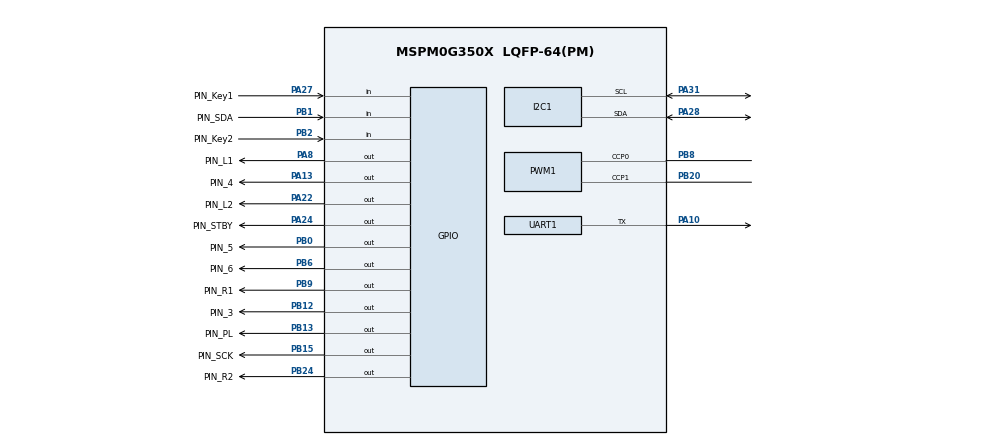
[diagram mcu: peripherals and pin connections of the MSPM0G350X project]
/**
 *
 * @cliArgs --device "MSPM0G350X" --part "Default" --package "LQFP-64(PM)" --product "mspm0_sdk@2.11.00.07"
 * @versions {"tool":"1.28.0+4696"}
 */

/**
 * Import the modules used in this configuration.
 */
const GPIO    = scripting.addModule("/ti/driverlib/GPIO", {}, false);
const GPIO1   = GPIO.addInstance();
const GPIO2   = GPIO.addInstance();
const GPIO3   = GPIO.addInstance();
const GPIO4   = GPIO.addInstance();
const GPIO5   = GPIO.addInstance();
const I2C     = scripting.addModule("/ti/driverlib/I2C", {}, false);
const I2C1    = I2C.addInstance();
const PWM     = scripting.addModule("/ti/driverlib/PWM", {}, false);
const PWM1    = PWM.addInstance();
const SYSCTL  = scripting.addModule("/ti/driverlib/SYSCTL");
const SYSTICK = scripting.addModule("/ti/driverlib/SYSTICK");
const UART    = scripting.addModule("/ti/driverlib/UART", {}, false);
const UART1   = UART.addInstance();

/**
 * Write custom configuration values to the imported modules.
 */
GPIO1.$name                          = "GPIO_Motor";
GPIO1.associatedPins.create(5);
GPIO1.associatedPins[0].$name        = "PIN_L1";
GPIO1.associatedPins[0].assignedPort = "PORTA";
GPIO1.associatedPins[0].assignedPin  = "8";
GPIO1.associatedPins[0].pin.$assign  = "PA8";
GPIO1.associatedPins[1].$name        = "PIN_L2";
GPIO1.associatedPins[1].assignedPort = "PORTA";
GPIO1.associatedPins[1].assignedPin  = "22";
GPIO1.associatedPins[1].pin.$assign  = "PA22";
GPIO1.associatedPins[2].$name        = "PIN_R1";
GPIO1.associatedPins[2].assignedPort = "PORTB";
GPIO1.associatedPins[2].assignedPin  = "9";
GPIO1.associatedPins[2].pin.$assign  = "PB9";
GPIO1.associatedPins[3].$name        = "PIN_R2";
GPIO1.associatedPins[3].assignedPort = "PORTB";
GPIO1.associatedPins[3].assignedPin  = "24";
GPIO1.associatedPins[3].pin.$assign  = "PB24";
GPIO1.associatedPins[4].$name        = "PIN_STBY";
GPIO1.associatedPins[4].assignedPort = "PORTA";
GPIO1.associatedPins[4].assignedPin  = "24";
GPIO1.associatedPins[4].pin.$assign  = "PA24";

const Board = scripting.addModule("/ti/driverlib/Board", {}, false);

GPIO2.$name                          = "GPIO_LED";
GPIO2.associatedPins[0].assignedPort = "PORTA";
GPIO2.associatedPins[0].$name        = "PIN_LED";
GPIO2.associatedPins[0].assignedPin  = "0";

GPIO3.$name                              = "GPIO_BUTTON";
GPIO3.associatedPins.create(3);
GPIO3.associatedPins[0].$name            = "PIN_BUTTON";
GPIO3.associatedPins[0].direction        = "INPUT";
GPIO3.associatedPins[0].assignedPort     = "PORTA";
GPIO3.associatedPins[0].assignedPin      = "18";
GPIO3.associatedPins[0].internalResistor = "PULL_DOWN";
GPIO3.associatedPins[1].$name            = "PIN_Key1";
GPIO3.associatedPins[1].direction        = "INPUT";
GPIO3.associatedPins[1].internalResistor = "PULL_UP";
GPIO3.associatedPins[1].pin.$assign      = "PA27";
GPIO3.associatedPins[2].$name            = "PIN_Key2";
GPIO3.associatedPins[2].direction        = "INPUT";
GPIO3.associatedPins[2].internalResistor = "PULL_UP";
GPIO3.associatedPins[2].pin.$assign      = "PB2";

GPIO4.$name                          = "GPIO_Sensor";
GPIO4.associatedPins.create(3);
GPIO4.associatedPins[0].assignedPort = "PORTB";
GPIO4.associatedPins[0].$name        = "PIN_PL";
GPIO4.associatedPins[0].pin.$assign  = "PB13";
GPIO4.associatedPins[1].$name        = "PIN_SCK";
GPIO4.associatedPins[1].assignedPort = "PORTB";
GPIO4.associatedPins[1].pin.$assign  = "PB15";
GPIO4.associatedPins[2].assignedPort = "PORTB";
GPIO4.associatedPins[2].$name        = "PIN_SDA";
GPIO4.associatedPins[2].direction    = "INPUT";
GPIO4.associatedPins[2].pin.$assign  = "PB1";

GPIO5.$name                         = "GPIO_Conder";
GPIO5.associatedPins.create(4);
GPIO5.associatedPins[0].$name       = "PIN_3";
GPIO5.associatedPins[0].pin.$assign = "PB12";
GPIO5.associatedPins[1].$name       = "PIN_4";
GPIO5.associatedPins[1].pin.$assign = "PA13";
GPIO5.associatedPins[2].$name       = "PIN_5";
GPIO5.associatedPins[2].pin.$assign = "PB0";
GPIO5.associatedPins[3].$name       = "PIN_6";
GPIO5.associatedPins[3].pin.$assign = "PB6";

I2C1.$name                             = "I2C_OLED";
I2C1.basicEnableController             = true;
I2C1.basicControllerStandardBusSpeed   = "Fast";
I2C1.peripheral.$assign                = "I2C0";
I2C1.peripheral.sdaPin.$assign         = "PA28";
I2C1.peripheral.sclPin.$assign         = "PA31";
I2C1.sdaPinConfig.hideOutputInversion  = scripting.forceWrite(false);
I2C1.sdaPinConfig.onlyInternalResistor = scripting.forceWrite(false);
I2C1.sdaPinConfig.passedPeripheralType = scripting.forceWrite("Digital");
I2C1.sdaPinConfig.$name                = "ti_driverlib_gpio_GPIOPinGeneric2";
I2C1.sclPinConfig.hideOutputInversion  = scripting.forceWrite(false);
I2C1.sclPinConfig.onlyInternalResistor = scripting.forceWrite(false);
I2C1.sclPinConfig.passedPeripheralType = scripting.forceWrite("Digital");
I2C1.sclPinConfig.$name                = "ti_driverlib_gpio_GPIOPinGeneric3";

PWM1.$name                              = "PWM_Motor";
PWM1.timerStartTimer                    = true;
PWM1.peripheral.$assign                 = "TIMA0";
PWM1.peripheral.ccp0Pin.$assign         = "PB8";
PWM1.peripheral.ccp1Pin.$assign         = "PB20";
PWM1.PWM_CHANNEL_0.$name                = "ti_driverlib_pwm_PWMTimerCC0";
PWM1.PWM_CHANNEL_1.$name                = "ti_driverlib_pwm_PWMTimerCC1";
PWM1.ccp0PinConfig.direction            = scripting.forceWrite("OUTPUT");
PWM1.ccp0PinConfig.hideOutputInversion  = scripting.forceWrite(false);
PWM1.ccp0PinConfig.onlyInternalResistor = scripting.forceWrite(false);
PWM1.ccp0PinConfig.passedPeripheralType = scripting.forceWrite("Digital");
PWM1.ccp0PinConfig.$name                = "ti_driverlib_gpio_GPIOPinGeneric0";
PWM1.ccp1PinConfig.direction            = scripting.forceWrite("OUTPUT");
PWM1.ccp1PinConfig.hideOutputInversion  = scripting.forceWrite(false);
PWM1.ccp1PinConfig.onlyInternalResistor = scripting.forceWrite(false);
PWM1.ccp1PinConfig.passedPeripheralType = scripting.forceWrite("Digital");
PWM1.ccp1PinConfig.$name                = "ti_driverlib_gpio_GPIOPinGeneric1";

SYSCTL.forceDefaultClkConfig = true;

SYSTICK.periodEnable  = true;
SYSTICK.systickEnable = true;
SYSTICK.period        = 32;

UART1.$name                    = "UART_0";
UART1.targetBaudRate           = 115200;
UART1.direction                = "TX";
UART1.txPinConfig.$name        = "ti_driverlib_gpio_GPIOPinGeneric4";
UART1.peripheral.$assign       = "UART0";
UART1.peripheral.txPin.$assign = "PA10";

/**
 * Pinmux solution for unlocked pins/peripherals. This ensures that minor changes to the automatic solver in a future
 * version of the tool will not impact the pinmux you originally saw.  These lines can be completely deleted in order to
 * re-solve from scratch.
 */
Board.peripheral.$suggestSolution            = "DEBUGSS";
Board.peripheral.swclkPin.$suggestSolution   = "PA20";
Board.peripheral.swdioPin.$suggestSolution   = "PA19";
GPIO2.associatedPins[0].pin.$suggestSolution = "PA0";
GPIO3.associatedPins[0].pin.$suggestSolution = "PA18";
SYSCTL.peripheral.$suggestSolution           = "SYSCTL";
